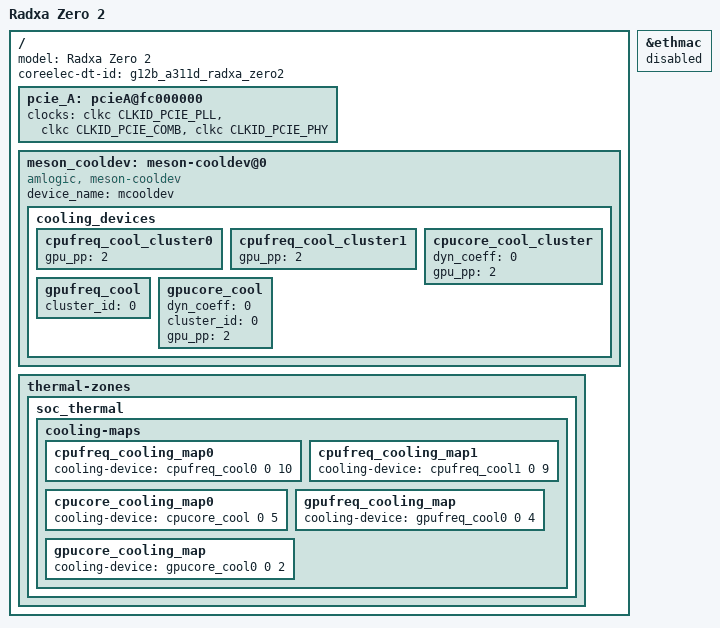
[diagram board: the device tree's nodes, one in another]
#include "coreelec_g12b.dtsi"

/{
	model = "Radxa Zero 2";
	coreelec-dt-id = "g12b_a311d_radxa_zero2";

	/delete-node/ memory@00000000;

	pcie_A: pcieA@fc000000 {
		clocks = <&clkc CLKID_PCIE_PLL
			&clkc CLKID_PCIE_COMB
			&clkc CLKID_PCIE_PHY>;
		clock-names = "pcie_refpll",
				"pcie",
				"pcie_phy";
	};

	meson_cooldev: meson-cooldev@0 {
			status = "okay";
			compatible = "amlogic, meson-cooldev";
			device_name = "mcooldev";
			cooling_devices {
				cpufreq_cool_cluster0 {
					gpu_pp = <2>;
				};
				cpufreq_cool_cluster1 {
					gpu_pp = <2>;
				};
				cpucore_cool_cluster {
					dyn_coeff = <0>;
					gpu_pp = <2>;
				};
				gpufreq_cool {
					cluster_id = <0>;
				};
				gpucore_cool {
					dyn_coeff = <0>;
					cluster_id = <0>;
					gpu_pp = <2>;
				};
			};
		};

	thermal-zones {
		soc_thermal: soc_thermal {
			cooling-maps {
				cpufreq_cooling_map0 {
					cooling-device = <&cpufreq_cool0 0 10>;
				};
				cpufreq_cooling_map1 {
					cooling-device = <&cpufreq_cool1 0 9>;
				};
				cpucore_cooling_map0 {
					cooling-device = <&cpucore_cool 0 5>;
				};
				gpufreq_cooling_map {
					cooling-device = <&gpufreq_cool0 0 4>;
				};
				gpucore_cooling_map {
					cooling-device = <&gpucore_cool0 0 2>;
				};
			};
		};
	};
};

&ethmac {
	status = "disabled";
};
